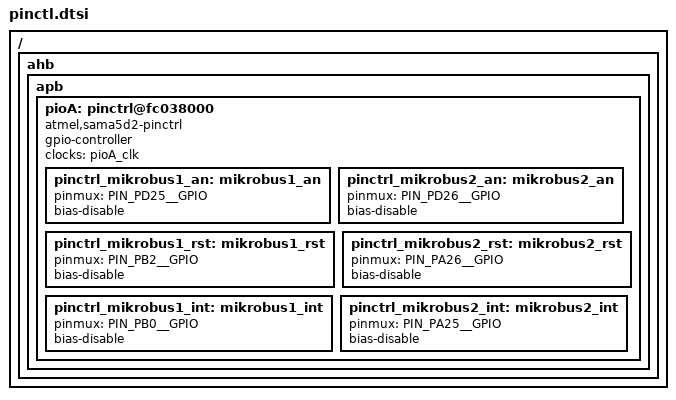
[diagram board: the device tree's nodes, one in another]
/* microElk */
/ {
    ahb { /* Advanced high-speed bus */
        apb { /* Advanced peripheral bus */
            /**************/
            /*** PINCTL ***/
            /**************/
            pioA: pinctrl@fc038000 {
                compatible      = "atmel,sama5d2-pinctrl";
                gpio-controller;
                #gpio-cells         = <2>;
                clocks              = <&pioA_clk>;
                /****************/
                /*** microBUS ***/
                /****************/
                pinctrl_mikrobus1_an: mikrobus1_an {
                    pinmux =        <PIN_PD25__GPIO>;
                    bias-disable;
                }; /* mikrobus1_an */
                pinctrl_mikrobus2_an: mikrobus2_an {
                    pinmux =        <PIN_PD26__GPIO>;
                    bias-disable;
                }; /* mikrobus2_an */
                pinctrl_mikrobus1_rst: mikrobus1_rst {
                    pinmux =        <PIN_PB2__GPIO>;
                    bias-disable;
                }; /* mikrobus1_rst */
                pinctrl_mikrobus2_rst: mikrobus2_rst {
                    pinmux =        <PIN_PA26__GPIO>;
                    bias-disable;
                }; /* mikrobus2_rst */
                pinctrl_mikrobus1_int: mikrobus1_int {
                    pinmux =        <PIN_PB0__GPIO>;
                    bias-disable;
                }; /* mikrobus1_int */
                pinctrl_mikrobus2_int: mikrobus2_int {
                    pinmux =        <PIN_PA25__GPIO>;
                    bias-disable;
                }; /* mikrobus2_int */
            }; /* pinctrl@fc038000 */
        }; /* apb */
    }; /* ahb */
}; /* / */
